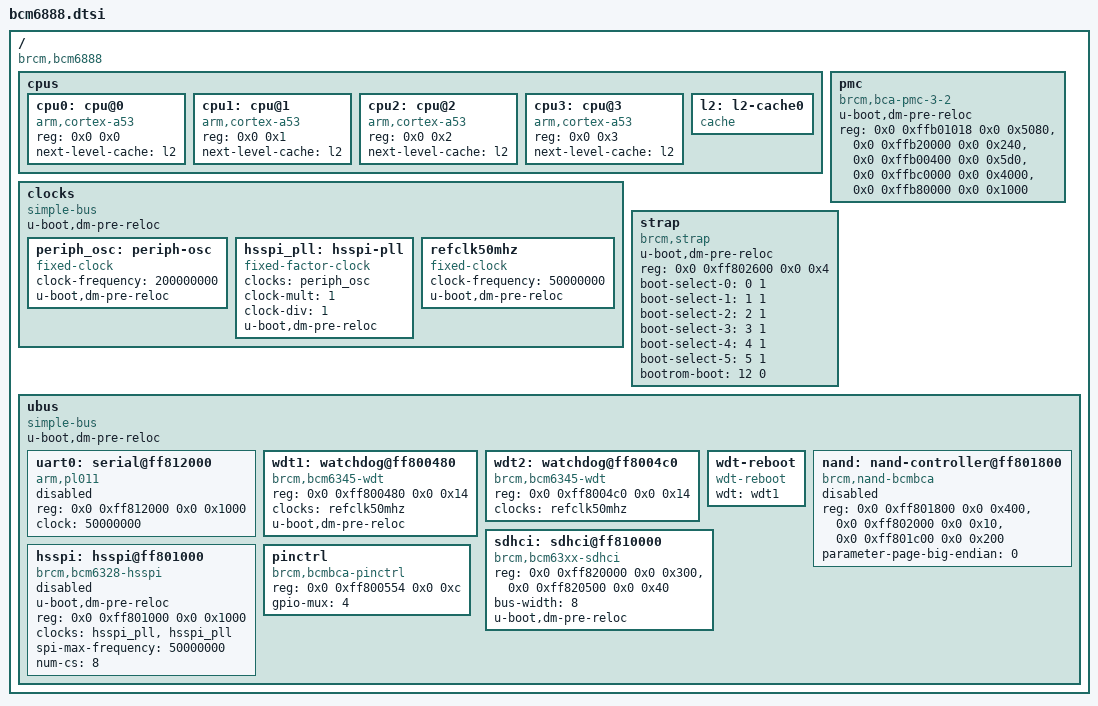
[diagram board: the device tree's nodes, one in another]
// SPDX-License-Identifier: GPL-2.0+
/*
 *  Copyright 2020 Broadcom Ltd.
 */

#include "skeleton64.dtsi"

/ {
	compatible = "brcm,bcm6888";
	#address-cells = <2>;
	#size-cells = <2>;

	cpus {
		#address-cells = <2>;
		#size-cells = <0>;

		cpu0: cpu@0 {
			compatible = "arm,cortex-a53", "arm,armv8";
			device_type = "cpu";
			reg = <0x0 0x0>;
			next-level-cache = <&l2>;
		};

		cpu1: cpu@1 {
			compatible = "arm,cortex-a53", "arm,armv8";
			device_type = "cpu";
			reg = <0x0 0x1>;
			next-level-cache = <&l2>;
		};

		cpu2: cpu@2 {
			compatible = "arm,cortex-a53", "arm,armv8";
			device_type = "cpu";
			reg = <0x0 0x2>;
			next-level-cache = <&l2>;
		};

		cpu3: cpu@3 {
			compatible = "arm,cortex-a53", "arm,armv8";
			device_type = "cpu";
			reg = <0x0 0x3>;
			next-level-cache = <&l2>;
		};

		l2: l2-cache0 {
			compatible = "cache";
		};
	};

	clocks {
		compatible = "simple-bus";
		#address-cells = <2>;
		#size-cells = <2>;
		ranges;
		u-boot,dm-pre-reloc;

		periph_osc: periph-osc {
			compatible = "fixed-clock";
			#clock-cells = <0>;
			clock-frequency = <200000000>;
			u-boot,dm-pre-reloc;
		};

		hsspi_pll: hsspi-pll {
			compatible = "fixed-factor-clock";
			#clock-cells = <0>;
			clocks = <&periph_osc>;
			clock-mult = <1>;
			clock-div = <1>;
			u-boot,dm-pre-reloc;
		};

		refclk50mhz: refclk50mhz {
			compatible = "fixed-clock";
			#clock-cells = <0>;
			clock-frequency = <50000000>;
			u-boot,dm-pre-reloc;
		};
	};

	pmc {
		u-boot,dm-pre-reloc;
		compatible = "brcm,bca-pmc-3-2";
		reg-names = "pmc", "procmon", "maestro", "itcm", "dtcm";
		reg = <0x0 0xffb01018 0x0 0x5080>,
			  <0x0 0xffb20000 0x0 0x240>,
			  <0x0 0xffb00400 0x0 0x5d0>,
			  <0x0 0xffbc0000 0x0 0x4000>,
			  <0x0 0xffb80000 0x0 0x1000>;
	};

	strap: strap {
		u-boot,dm-pre-reloc;
		compatible = "brcm,strap";
		reg = <0x0 0xff802600 0x0 0x4>;
		boot-select-0=<0 1>;
		boot-select-1=<1 1>;
		boot-select-2=<2 1>;
		boot-select-3=<3 1>;
		boot-select-4=<4 1>;
		boot-select-5=<5 1>;
		bootrom-boot=<12 0>;
	};

	ubus {
		compatible = "simple-bus";
		#address-cells = <2>;
		#size-cells = <2>;
		u-boot,dm-pre-reloc;

		uart0: serial@ff812000 {
			compatible = "arm,pl011", "arm,primecell";
			reg = <0x0 0xff812000 0x0 0x1000>;
			clock = <50000000>;

			status = "disabled";
		};

		wdt1: watchdog@ff800480 {
			compatible = "brcm,bcm6345-wdt";
			reg = <0x0 0xff800480 0x0 0x14>;
			clocks = <&refclk50mhz>;
			u-boot,dm-pre-reloc;
		};

		wdt2: watchdog@ff8004c0 {
			compatible = "brcm,bcm6345-wdt";
			reg = <0x0 0xff8004c0 0x0 0x14>;
			clocks = <&refclk50mhz>;
		};

		wdt-reboot {
			compatible = "wdt-reboot";
			wdt = <&wdt1>;
		};

		nand: nand-controller@ff801800 {
			compatible = "brcm,nand-bcmbca",
					 "brcm,brcmnand-v7.1",
					 "brcm,brcmnand";
			reg-names = "nand", "nand-int-base", "nand-cache";
			reg = <0x0 0xff801800 0x0 0x400>,
				  <0x0 0xff802000 0x0 0x10>,
				  <0x0 0xff801c00 0x0 0x200>;
			parameter-page-big-endian = <0>;

			status = "disabled";
		};

		sdhci: sdhci@ff810000 {
			compatible = "brcm,bcm63xx-sdhci",
						"brcm,sdhci-brcmbca";
			reg-names = "sdhci-base", "sdhci-boot";
			reg = <0x0 0xff820000 0x0 0x300>,
				<0x0 0xff820500 0x0 0x40>;
			bus-width = <8>;
			u-boot,dm-pre-reloc;
		};

		hsspi: hsspi@ff801000 {
			compatible = "brcm,bcm6328-hsspi";
			#address-cells = <0x1>;
			#size-cells = <0x0>;
			u-boot,dm-pre-reloc;

			reg = <0x0 0xff801000 0x0 0x1000>;
			clocks = <&hsspi_pll>, <&hsspi_pll>;
			clock-names = "hsspi", "pll";
			spi-max-frequency = <50000000>;
			num-cs = <8>;
			status = "disabled";
		};

		pinctrl: pinctrl {
			compatible = "brcm,bcmbca-pinctrl";
			reg = <0x0 0xff800554 0x0 0xc>;
			gpio-mux = <4>;
		};
	};
};

#include "bcm6888-pinctrl.dtsi"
